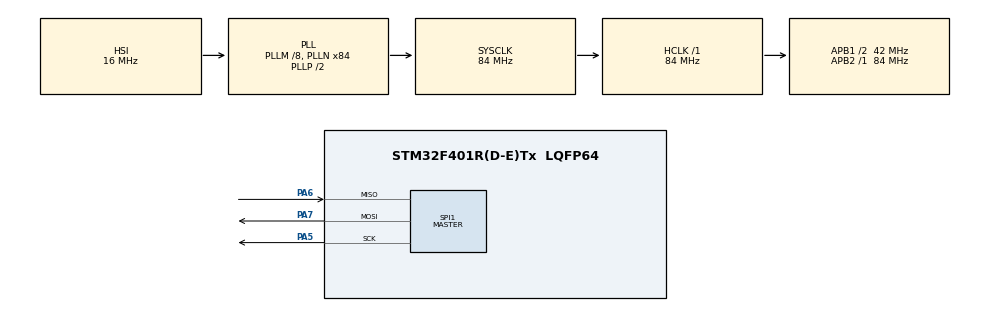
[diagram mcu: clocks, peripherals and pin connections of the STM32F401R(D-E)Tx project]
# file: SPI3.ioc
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Dma.Request0=SPI1_TX
Dma.Request1=SPI1_RX
Dma.SPI1_RX.1.Direction=DMA_PERIPH_TO_MEMORY
Dma.SPI1_RX.1.FIFOMode=DMA_FIFOMODE_DISABLE
Dma.SPI1_RX.1.Instance=DMA2_Stream0
Dma.SPI1_RX.1.MemDataAlignment=DMA_MDATAALIGN_BYTE
Dma.SPI1_RX.1.MemInc=DMA_MINC_ENABLE
Dma.SPI1_RX.1.Mode=DMA_NORMAL
Dma.SPI1_RX.1.PeriphDataAlignment=DMA_PDATAALIGN_BYTE
Dma.SPI1_RX.1.PeriphInc=DMA_PINC_DISABLE
Dma.SPI1_RX.1.Priority=DMA_PRIORITY_LOW
Dma.SPI1_TX.0.Direction=DMA_MEMORY_TO_PERIPH
Dma.SPI1_TX.0.FIFOMode=DMA_FIFOMODE_DISABLE
Dma.SPI1_TX.0.Instance=DMA2_Stream3
Dma.SPI1_TX.0.MemDataAlignment=DMA_MDATAALIGN_BYTE
Dma.SPI1_TX.0.MemInc=DMA_MINC_ENABLE
Dma.SPI1_TX.0.Mode=DMA_NORMAL
Dma.SPI1_TX.0.PeriphDataAlignment=DMA_PDATAALIGN_BYTE
Dma.SPI1_TX.0.PeriphInc=DMA_PINC_DISABLE
Dma.SPI1_TX.0.Priority=DMA_PRIORITY_LOW
Mcu.Family=STM32F4
Mcu.Name=STM32F401R(D-E)Tx
Mcu.Package=LQFP64
NVIC.DMA2_Stream0_IRQn=true\:0\:0\:false\:false\:true
NVIC.DMA2_Stream3_IRQn=true\:0\:0\:false\:false\:true
NVIC.PriorityGroup=NVIC_PRIORITYGROUP_4
PA5.Mode=Full_Duplex_Master
PA5.Signal=SPI1_SCK
PA6.Mode=Full_Duplex_Master
PA6.Signal=SPI1_MISO
PA7.Mode=Full_Duplex_Master
PA7.Signal=SPI1_MOSI
ProjectManager.HeapSize=0x200
ProjectManager.StackSize=0x400
ProjectManager.TargetToolchain=SW4STM32
RCC.48MHZClocksFreq_Value=42000000
RCC.AHBFreq_Value=84000000
RCC.APB1CLKDivider=RCC_HCLK_DIV2
RCC.APB1Freq_Value=42000000
RCC.APB1TimFreq_Value=84000000
RCC.APB2Freq_Value=84000000
RCC.APB2TimFreq_Value=84000000
RCC.CortexFreq_Value=84000000
RCC.HCLKFreq_Value=84000000
RCC.HSE_VALUE=25000000
RCC.HSI_VALUE=16000000
RCC.LSE_VALUE=32768
RCC.PLLM=8
RCC.PLLN=84
RCC.SYSCLKFreq_VALUE=84000000
RCC.SYSCLKSource=RCC_SYSCLKSOURCE_PLLCLK
RCC.VCOOutputFreq_Value=168000000
SPI1.Mode=SPI_MODE_MASTER
board=SPI3

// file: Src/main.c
/**
  ******************************************************************************
  * File Name          : main.c
  * Description        : Main program body
  ******************************************************************************
  *
  * COPYRIGHT(c) 2016 STMicroelectronics
  *
  * Redistribution and use in source and binary forms, with or without modification,
  * are permitted provided that the following conditions are met:
  *   1. Redistributions of source code must retain the above copyright notice,
  *      this list of conditions and the following disclaimer.
  *   2. Redistributions in binary form must reproduce the above copyright notice,
  *      this list of conditions and the following disclaimer in the documentation
  *      and/or other materials provided with the distribution.
  *   3. Neither the name of STMicroelectronics nor the names of its contributors
  *      may be used to endorse or promote products derived from this software
  *      without specific prior written permission.
  *
  * THIS SOFTWARE IS PROVIDED BY THE COPYRIGHT HOLDERS AND CONTRIBUTORS "AS IS"
  * AND ANY EXPRESS OR IMPLIED WARRANTIES, INCLUDING, BUT NOT LIMITED TO, THE
  * IMPLIED WARRANTIES OF MERCHANTABILITY AND FITNESS FOR A PARTICULAR PURPOSE ARE
  * DISCLAIMED. IN NO EVENT SHALL THE COPYRIGHT HOLDER OR CONTRIBUTORS BE LIABLE
  * FOR ANY DIRECT, INDIRECT, INCIDENTAL, SPECIAL, EXEMPLARY, OR CONSEQUENTIAL
  * DAMAGES (INCLUDING, BUT NOT LIMITED TO, PROCUREMENT OF SUBSTITUTE GOODS OR
  * SERVICES; LOSS OF USE, DATA, OR PROFITS; OR BUSINESS INTERRUPTION) HOWEVER
  * CAUSED AND ON ANY THEORY OF LIABILITY, WHETHER IN CONTRACT, STRICT LIABILITY,
  * OR TORT (INCLUDING NEGLIGENCE OR OTHERWISE) ARISING IN ANY WAY OUT OF THE USE
  * OF THIS SOFTWARE, EVEN IF ADVISED OF THE POSSIBILITY OF SUCH DAMAGE.
  *
  ******************************************************************************
  */
#include "stm32f4xx_hal.h"
#include "dma.h"
#include "spi.h"
#include "gpio.h"

/* USER CODE BEGIN PV */
/* Private variables ---------------------------------------------------------*/
uint8_t buffer_tx[10]={'H','o','l','a',' ','P','a','c','o','\n'};
uint8_t buffer_rx[10];
/* USER CODE END PV */

void SystemClock_Config(void);
void Error_Handler(void);

/* USER CODE BEGIN PFP */
/* Private function prototypes -----------------------------------------------*/

/* USER CODE END PFP */

/* USER CODE BEGIN 0 */
void HAL_SPI_TxRxCpltCallback(SPI_HandleTypeDef *hspi){
	while(1);
}

/* USER CODE END 0 */

int main(void)
{

  /* MCU Configuration----------------------------------------------------------*/

  /* Reset of all peripherals, Initializes the Flash interface and the Systick. */
  HAL_Init();

  /* Configure the system clock */
  SystemClock_Config();

  /* Initialize all configured peripherals */
  MX_GPIO_Init();
  MX_DMA_Init();
  MX_SPI1_Init();

  /* USER CODE BEGIN 2 */
HAL_SPI_TransmitReceive_DMA(&hspi1,buffer_tx,buffer_rx,10);
  /* USER CODE END 2 */

  /* Infinite loop */
  while (1)
  {

  }

}

/** System Clock Configuration
*/
void SystemClock_Config(void)
{

  RCC_OscInitTypeDef RCC_OscInitStruct;
  RCC_ClkInitTypeDef RCC_ClkInitStruct;

  __HAL_RCC_PWR_CLK_ENABLE();

  __HAL_PWR_VOLTAGESCALING_CONFIG(PWR_REGULATOR_VOLTAGE_SCALE2);

  RCC_OscInitStruct.OscillatorType = RCC_OSCILLATORTYPE_HSI;
  RCC_OscInitStruct.HSIState = RCC_HSI_ON;
  RCC_OscInitStruct.HSICalibrationValue = 16;
  RCC_OscInitStruct.PLL.PLLState = RCC_PLL_ON;
  RCC_OscInitStruct.PLL.PLLSource = RCC_PLLSOURCE_HSI;
  RCC_OscInitStruct.PLL.PLLM = 8;
  RCC_OscInitStruct.PLL.PLLN = 84;
  RCC_OscInitStruct.PLL.PLLP = RCC_PLLP_DIV2;
  RCC_OscInitStruct.PLL.PLLQ = 4;
  if (HAL_RCC_OscConfig(&RCC_OscInitStruct) != HAL_OK)
  {
    Error_Handler();
  }

  RCC_ClkInitStruct.ClockType = RCC_CLOCKTYPE_HCLK|RCC_CLOCKTYPE_SYSCLK
                              |RCC_CLOCKTYPE_PCLK1|RCC_CLOCKTYPE_PCLK2;
  RCC_ClkInitStruct.SYSCLKSource = RCC_SYSCLKSOURCE_PLLCLK;
  RCC_ClkInitStruct.AHBCLKDivider = RCC_SYSCLK_DIV1;
  RCC_ClkInitStruct.APB1CLKDivider = RCC_HCLK_DIV2;
  RCC_ClkInitStruct.APB2CLKDivider = RCC_HCLK_DIV1;
  if (HAL_RCC_ClockConfig(&RCC_ClkInitStruct, FLASH_LATENCY_2) != HAL_OK)
  {
    Error_Handler();
  }

  HAL_SYSTICK_Config(HAL_RCC_GetHCLKFreq()/1000);

  HAL_SYSTICK_CLKSourceConfig(SYSTICK_CLKSOURCE_HCLK);

  /* SysTick_IRQn interrupt configuration */
  HAL_NVIC_SetPriority(SysTick_IRQn, 0, 0);
}

void Error_Handler(void)
{
  while(1)
  {
  }
}

/************************ (C) COPYRIGHT STMicroelectronics *****END OF FILE****/
